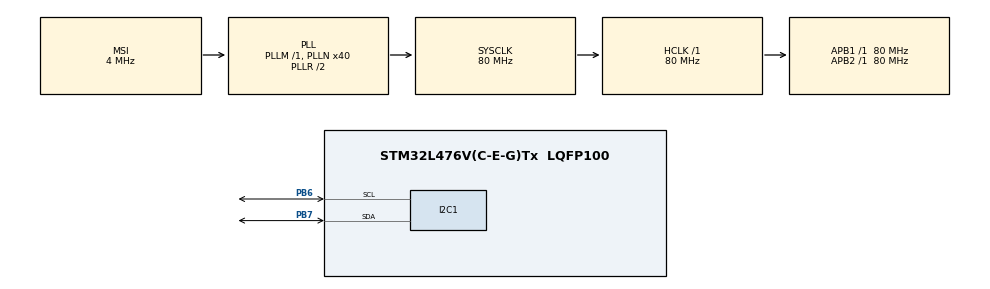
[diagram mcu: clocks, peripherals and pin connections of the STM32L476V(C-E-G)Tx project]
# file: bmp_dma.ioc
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Dma.I2C1_RX.0.Direction=DMA_PERIPH_TO_MEMORY
Dma.I2C1_RX.0.Instance=DMA1_Channel7
Dma.I2C1_RX.0.MemDataAlignment=DMA_MDATAALIGN_BYTE
Dma.I2C1_RX.0.MemInc=DMA_MINC_ENABLE
Dma.I2C1_RX.0.Mode=DMA_NORMAL
Dma.I2C1_RX.0.PeriphDataAlignment=DMA_PDATAALIGN_BYTE
Dma.I2C1_RX.0.PeriphInc=DMA_PINC_DISABLE
Dma.I2C1_RX.0.Priority=DMA_PRIORITY_LOW
Dma.I2C1_TX.1.Direction=DMA_MEMORY_TO_PERIPH
Dma.I2C1_TX.1.Instance=DMA1_Channel6
Dma.I2C1_TX.1.MemDataAlignment=DMA_MDATAALIGN_BYTE
Dma.I2C1_TX.1.MemInc=DMA_MINC_ENABLE
Dma.I2C1_TX.1.Mode=DMA_NORMAL
Dma.I2C1_TX.1.PeriphDataAlignment=DMA_PDATAALIGN_BYTE
Dma.I2C1_TX.1.PeriphInc=DMA_PINC_DISABLE
Dma.I2C1_TX.1.Priority=DMA_PRIORITY_LOW
Dma.Request0=I2C1_RX
Dma.Request1=I2C1_TX
Mcu.Family=STM32L4
Mcu.Name=STM32L476V(C-E-G)Tx
Mcu.Package=LQFP100
NVIC.DMA1_Channel6_IRQn=true\:0\:0\:false\:false\:true\:false\:true
NVIC.DMA1_Channel7_IRQn=true\:0\:0\:false\:false\:true\:false\:true
NVIC.I2C1_EV_IRQn=true\:0\:0\:false\:false\:true\:true\:true
NVIC.PriorityGroup=NVIC_PRIORITYGROUP_4
PB6.Mode=I2C
PB6.Signal=I2C1_SCL
PB7.Mode=I2C
PB7.Signal=I2C1_SDA
PH0-OSC_IN\ (PH0).Mode=HSE-External-Oscillator
PH0-OSC_IN\ (PH0).Signal=RCC_OSC_IN
PH1-OSC_OUT\ (PH1).Mode=HSE-External-Oscillator
PH1-OSC_OUT\ (PH1).Signal=RCC_OSC_OUT
ProjectManager.HeapSize=0x200
ProjectManager.StackSize=0x400
ProjectManager.TargetToolchain=EWARM V8
RCC.ADCFreq_Value=16000000
RCC.AHBFreq_Value=80000000
RCC.APB1Freq_Value=80000000
RCC.APB1TimFreq_Value=80000000
RCC.APB2Freq_Value=80000000
RCC.APB2TimFreq_Value=80000000
RCC.CortexFreq_Value=80000000
RCC.HCLKFreq_Value=80000000
RCC.HSI_VALUE=16000000
RCC.LSE_VALUE=32768
RCC.MSI_VALUE=4000000
RCC.PLLN=40
RCC.SYSCLKFreq_VALUE=80000000
RCC.SYSCLKSource=RCC_SYSCLKSOURCE_PLLCLK
RCC.USBFreq_Value=16000000
RCC.VCOOutputFreq_Value=160000000
board=custom

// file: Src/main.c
/* USER CODE BEGIN Header */
/**
  ******************************************************************************
  * @file           : main.c
  * @brief          : Main program body
  ******************************************************************************
  * @attention
  *
  * <h2><center>&copy; Copyright (c) 2019 STMicroelectronics.
  * All rights reserved.</center></h2>
  *
  * This software component is licensed by ST under BSD 3-Clause license,
  * the "License"; You may not use this file except in compliance with the
  * License. You may obtain a copy of the License at:
  *                        opensource.org/licenses/BSD-3-Clause
  *
  ******************************************************************************
  */
/* USER CODE END Header */

#include "main.h"

/* USER CODE BEGIN Includes */
#include "bmp280.h"
/* USER CODE END Includes */

/* USER CODE BEGIN PD */
/**
 * BMP280 or BME280 address is 0x77 if SDO pin is high, and is 0x76 if
 * SDO pin is low.
 */
#define BMP280_I2C_ADDRESS_0  0x76
#define BMP280_I2C_ADDRESS_1  0x77
/* USER CODE END PD */

I2C_HandleTypeDef hi2c1;
DMA_HandleTypeDef hdma_i2c1_rx;
DMA_HandleTypeDef hdma_i2c1_tx;

/* USER CODE BEGIN PV */
BMP280_HandleTypedef bmp280;

float pressure, temperature, humidity;

uint16_t size;
uint8_t Data[256];

bool bme280p;
/* USER CODE END PV */

void SystemClock_Config(void);
static void MX_GPIO_Init(void);
static void MX_DMA_Init(void);
static void MX_I2C1_Init(void);
/* USER CODE BEGIN PFP */
static void MX_BMP_Init(void);
/* USER CODE END PFP */

int main(void)
{

  /* MCU Configuration--------------------------------------------------------*/

  /* Reset of all peripherals, Initializes the Flash interface and the Systick. */
  HAL_Init();

  /* Configure the system clock */
  SystemClock_Config();

  /* Initialize all configured peripherals */
  MX_GPIO_Init();
  MX_DMA_Init();
  MX_I2C1_Init();
  /* USER CODE BEGIN 2 */
  MX_BMP_Init();

  for (int i = 0; i < 10; i++)
  {
    if (!bmp280_read_float_dma(&bmp280, &temperature, &pressure, &humidity))
    {
      printf("Temperature/pressure reading failed\n");
    }
    printf("Pressure: %.2f Pa, Temperature: %.2f C", pressure, temperature);
    if (!bme280p)
    {
      printf(", Humidity: %.2f\n", humidity);
    }
    printf("\n");
    HAL_Delay(1000);
  }
  /* USER CODE END 2 */

  /* Infinite loop */
  /* USER CODE BEGIN WHILE */
  while (1)
  {
    printf("hello world!\n");
    HAL_Delay(1000);
    /* USER CODE END WHILE */

  }
}

void SystemClock_Config(void)
{
  RCC_OscInitTypeDef RCC_OscInitStruct = {0};
  RCC_ClkInitTypeDef RCC_ClkInitStruct = {0};
  RCC_PeriphCLKInitTypeDef PeriphClkInit = {0};

  /** Initializes the CPU, AHB and APB busses clocks
  */
  RCC_OscInitStruct.OscillatorType = RCC_OSCILLATORTYPE_MSI;
  RCC_OscInitStruct.MSIState = RCC_MSI_ON;
  RCC_OscInitStruct.MSICalibrationValue = 0;
  RCC_OscInitStruct.MSIClockRange = RCC_MSIRANGE_6;
  RCC_OscInitStruct.PLL.PLLState = RCC_PLL_ON;
  RCC_OscInitStruct.PLL.PLLSource = RCC_PLLSOURCE_MSI;
  RCC_OscInitStruct.PLL.PLLM = 1;
  RCC_OscInitStruct.PLL.PLLN = 40;
  RCC_OscInitStruct.PLL.PLLP = RCC_PLLP_DIV7;
  RCC_OscInitStruct.PLL.PLLQ = RCC_PLLQ_DIV2;
  RCC_OscInitStruct.PLL.PLLR = RCC_PLLR_DIV2;
  if (HAL_RCC_OscConfig(&RCC_OscInitStruct) != HAL_OK)
  {
    Error_Handler();
  }
  /** Initializes the CPU, AHB and APB busses clocks
  */
  RCC_ClkInitStruct.ClockType = RCC_CLOCKTYPE_HCLK|RCC_CLOCKTYPE_SYSCLK
                              |RCC_CLOCKTYPE_PCLK1|RCC_CLOCKTYPE_PCLK2;
  RCC_ClkInitStruct.SYSCLKSource = RCC_SYSCLKSOURCE_PLLCLK;
  RCC_ClkInitStruct.AHBCLKDivider = RCC_SYSCLK_DIV1;
  RCC_ClkInitStruct.APB1CLKDivider = RCC_HCLK_DIV1;
  RCC_ClkInitStruct.APB2CLKDivider = RCC_HCLK_DIV1;

  if (HAL_RCC_ClockConfig(&RCC_ClkInitStruct, FLASH_LATENCY_4) != HAL_OK)
  {
    Error_Handler();
  }
  PeriphClkInit.PeriphClockSelection = RCC_PERIPHCLK_I2C1;
  PeriphClkInit.I2c1ClockSelection = RCC_I2C1CLKSOURCE_PCLK1;
  if (HAL_RCCEx_PeriphCLKConfig(&PeriphClkInit) != HAL_OK)
  {
    Error_Handler();
  }
  /** Configure the main internal regulator output voltage
  */
  if (HAL_PWREx_ControlVoltageScaling(PWR_REGULATOR_VOLTAGE_SCALE1) != HAL_OK)
  {
    Error_Handler();
  }
}

static void MX_I2C1_Init(void)
{

  hi2c1.Instance = I2C1;
  hi2c1.Init.Timing = 0x10909CEC;
  hi2c1.Init.OwnAddress1 = 0;
  hi2c1.Init.AddressingMode = I2C_ADDRESSINGMODE_7BIT;
  hi2c1.Init.DualAddressMode = I2C_DUALADDRESS_DISABLE;
  hi2c1.Init.OwnAddress2 = 0;
  hi2c1.Init.OwnAddress2Masks = I2C_OA2_NOMASK;
  hi2c1.Init.GeneralCallMode = I2C_GENERALCALL_DISABLE;
  hi2c1.Init.NoStretchMode = I2C_NOSTRETCH_DISABLE;
  if (HAL_I2C_Init(&hi2c1) != HAL_OK)
  {
    Error_Handler();
  }
  /** Configure Analogue filter
  */
  if (HAL_I2CEx_ConfigAnalogFilter(&hi2c1, I2C_ANALOGFILTER_ENABLE) != HAL_OK)
  {
    Error_Handler();
  }
  /** Configure Digital filter
  */
  if (HAL_I2CEx_ConfigDigitalFilter(&hi2c1, 0) != HAL_OK)
  {
    Error_Handler();
  }

}

static void MX_DMA_Init(void)
{

  /* DMA controller clock enable */
  __HAL_RCC_DMA1_CLK_ENABLE();

  /* DMA interrupt init */
  /* DMA1_Channel6_IRQn interrupt configuration */
  HAL_NVIC_SetPriority(DMA1_Channel6_IRQn, 0, 0);
  HAL_NVIC_EnableIRQ(DMA1_Channel6_IRQn);
  /* DMA1_Channel7_IRQn interrupt configuration */
  HAL_NVIC_SetPriority(DMA1_Channel7_IRQn, 0, 0);
  HAL_NVIC_EnableIRQ(DMA1_Channel7_IRQn);

}

static void MX_GPIO_Init(void)
{

  /* GPIO Ports Clock Enable */
  __HAL_RCC_GPIOH_CLK_ENABLE();
  __HAL_RCC_GPIOB_CLK_ENABLE();

}

/* USER CODE BEGIN 4 */
static void MX_BMP_Init(void)
{
  bmp280_init_default_params(&bmp280.params);
  bmp280.addr = BMP280_I2C_ADDRESS_1;
  bmp280.i2c = &hi2c1;

  while (!bmp280_init(&bmp280, &bmp280.params))
  {
    printf("BMP280 initialization failed\n");
    HAL_Delay(2000);
  }
  bme280p = bmp280.id == BMP280_CHIP_ID;
  if (bme280p == true)
  {
    printf("BMP280: found BMP280\n");
  }
  else
  {
    printf("BMP280: found BME280\n");
  }
}

void DMA1_Channel7_IRQHandler(void)
{
  /* USER CODE BEGIN DMA1_Channel7_IRQn 0 */

  /* USER CODE END DMA1_Channel7_IRQn 0 */
  HAL_DMA_IRQHandler(&hdma_i2c1_rx);
  /* USER CODE BEGIN DMA1_Channel7_IRQn 1 */

  /* USER CODE END DMA1_Channel7_IRQn 1 */
}

void I2C1_EV_IRQHandler(void)
{
  /* USER CODE BEGIN I2C1_EV_IRQn 0 */

  /* USER CODE END I2C1_EV_IRQn 0 */
  HAL_I2C_EV_IRQHandler(&hi2c1);
  /* USER CODE BEGIN I2C1_EV_IRQn 1 */

  /* USER CODE END I2C1_EV_IRQn 1 */
}

void HAL_I2C_MemRxCpltCallback(I2C_HandleTypeDef *hi2c)
{
  printf("HAL_I2C_MemRxCpltCallback\n");
}
/* USER CODE END 4 */

void Error_Handler(void)
{
  /* USER CODE BEGIN Error_Handler_Debug */
  /* User can add his own implementation to report the HAL error return state */
  printf("Error\n");
  /* USER CODE END Error_Handler_Debug */
}

/************************ (C) COPYRIGHT STMicroelectronics *****END OF FILE****/
